AUTOSAR XML (schema 00046)
package /ComponentTypes
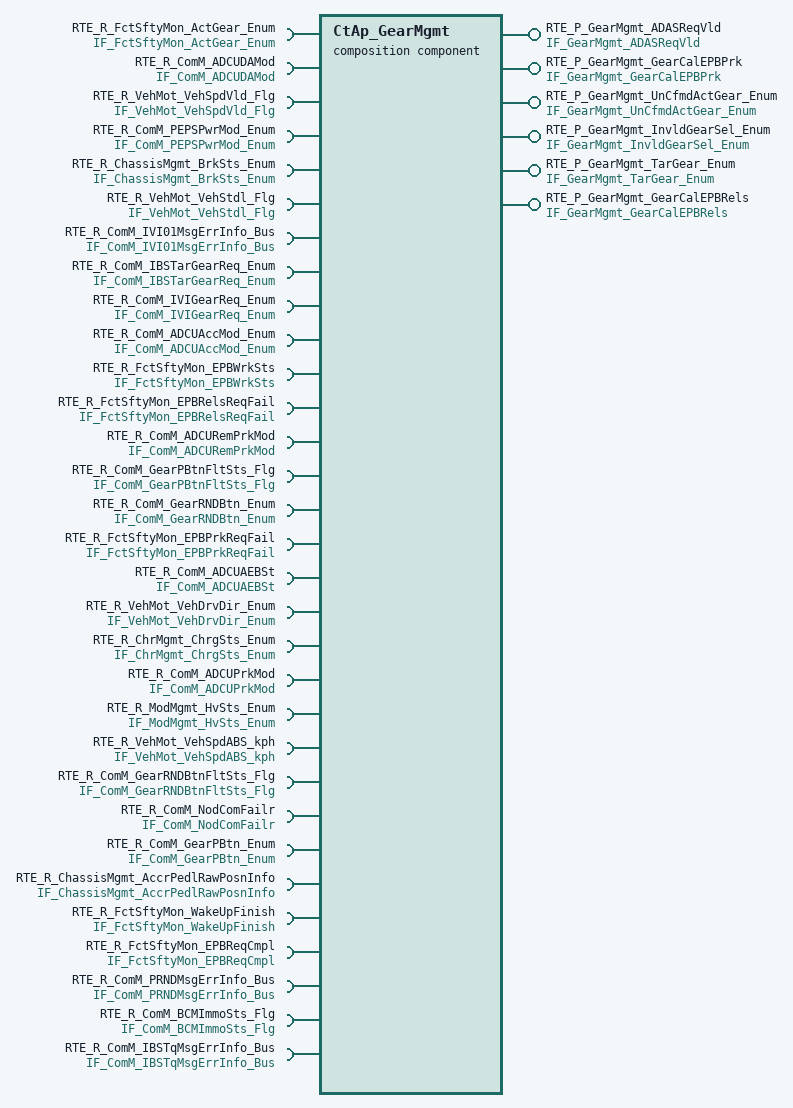
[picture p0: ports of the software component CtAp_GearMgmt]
  composition sw component type CtAp_GearMgmt
    30 x require port:
      RTE_R_FctSftyMon_ActGear_Enum: nonqueued-receiver-com-spec{data-element=tec_FctSftyMon_ActGear_Enum, filter=data-filter-type=ALWAYS, init-value=0}, required-interface=IF_FctSftyMon_ActGear_Enum
      RTE_R_ComM_ADCUDAMod: nonqueued-receiver-com-spec{data-element=tec_ComM_ADCUDAMod, filter=data-filter-type=ALWAYS, init-value=0}, required-interface=IF_ComM_ADCUDAMod
      RTE_R_VehMot_VehSpdVld_Flg: nonqueued-receiver-com-spec{data-element=tec_VehMot_VehSpdVld_Flg, filter=data-filter-type=ALWAYS, init-value=0}, required-interface=IF_VehMot_VehSpdVld_Flg
      RTE_R_ComM_PEPSPwrMod_Enum: nonqueued-receiver-com-spec{data-element=tec_ComM_PEPSPwrMod_Enum, filter=data-filter-type=ALWAYS, init-value=0}, required-interface=IF_ComM_PEPSPwrMod_Enum
      RTE_R_ChassisMgmt_BrkSts_Enum: nonqueued-receiver-com-spec{data-element=tec_ChassisMgmt_BrkSts_Enum, filter=data-filter-type=ALWAYS, init-value=0}, required-interface=IF_ChassisMgmt_BrkSts_Enum
      RTE_R_VehMot_VehStdl_Flg: nonqueued-receiver-com-spec{data-element=tec_VehMot_VehStdl_Flg, filter=data-filter-type=ALWAYS, init-value=0}, required-interface=IF_VehMot_VehStdl_Flg
      RTE_R_ComM_IVI01MsgErrInfo_Bus: required-interface=IF_ComM_IVI01MsgErrInfo_Bus
        required-com-specs:
          data-element=tec_ComM_IVI01CRCInfo_Bus, filter=data-filter-type=ALWAYS, init-value=fields=[ComM_MonStatIVI01CRCErrorInfo:0, ComM_MonResIVI01CRCErrorInfo:0, ComM_ErrStatIVI01CRCErrorInfo:0, ComM_ErrResIVI01CRCErrorInfo:0]
          data-element=tec_ComM_IVI01E2ETimeoutInfo_Bus, filter=data-filter-type=ALWAYS
      RTE_R_ComM_IBSTarGearReq_Enum: nonqueued-receiver-com-spec{data-element=tec_ComM_IBSTarGearReq_Enum, filter=data-filter-type=ALWAYS, init-value=0}, required-interface=IF_ComM_IBSTarGearReq_Enum
      RTE_R_ComM_IVIGearReq_Enum: nonqueued-receiver-com-spec{data-element=tec_ComM_IVIGearReq_Enum, filter=data-filter-type=ALWAYS, init-value=0}, required-interface=IF_ComM_IVIGearReq_Enum
      RTE_R_ComM_ADCUAccMod_Enum: nonqueued-receiver-com-spec{data-element=tec_ComM_ADCUAccMod_Enum, filter=data-filter-type=ALWAYS, init-value=0}, required-interface=IF_ComM_ADCUAccMod_Enum
      RTE_R_FctSftyMon_EPBWrkSts: nonqueued-receiver-com-spec{data-element=tec_FctSftyMon_EPBWrkSts, filter=data-filter-type=ALWAYS, init-value=0}, required-interface=IF_FctSftyMon_EPBWrkSts
      RTE_R_FctSftyMon_EPBRelsReqFail: nonqueued-receiver-com-spec{data-element=tec_FctSftyMon_EPBRelsReqFail, filter=data-filter-type=ALWAYS, init-value=0}, required-interface=IF_FctSftyMon_EPBRelsReqFail
      RTE_R_ComM_ADCURemPrkMod: nonqueued-receiver-com-spec{data-element=tec_ComM_ADCURemPrkMod, filter=data-filter-type=ALWAYS, init-value=0}, required-interface=IF_ComM_ADCURemPrkMod
      RTE_R_ComM_GearPBtnFltSts_Flg: nonqueued-receiver-com-spec{data-element=tec_ComM_GearPBtnFltSts_Flg, filter=data-filter-type=ALWAYS, init-value=0}, required-interface=IF_ComM_GearPBtnFltSts_Flg
      RTE_R_ComM_GearRNDBtn_Enum: nonqueued-receiver-com-spec{data-element=tec_ComM_GearRNDBtn_Enum, filter=data-filter-type=ALWAYS, init-value=0}, required-interface=IF_ComM_GearRNDBtn_Enum
      RTE_R_FctSftyMon_EPBPrkReqFail: nonqueued-receiver-com-spec{data-element=tec_FctSftyMon_EPBPrkReqFail, filter=data-filter-type=ALWAYS, init-value=0}, required-interface=IF_FctSftyMon_EPBPrkReqFail
      RTE_R_ComM_ADCUAEBSt: nonqueued-receiver-com-spec{data-element=tec_ComM_ADCUAEBSt, filter=data-filter-type=ALWAYS, init-value=0}, required-interface=IF_ComM_ADCUAEBSt
      RTE_R_VehMot_VehDrvDir_Enum: nonqueued-receiver-com-spec{data-element=tec_VehMot_VehDrvDir_Enum, filter=data-filter-type=ALWAYS, init-value=0}, required-interface=IF_VehMot_VehDrvDir_Enum
      RTE_R_ChrMgmt_ChrgSts_Enum: nonqueued-receiver-com-spec{data-element=tec_ChrMgmt_ChrgSts_Enum, filter=data-filter-type=ALWAYS, init-value=0}, required-interface=IF_ChrMgmt_ChrgSts_Enum
      RTE_R_ComM_ADCUPrkMod: nonqueued-receiver-com-spec{data-element=tec_ComM_ADCUPrkMod, filter=data-filter-type=ALWAYS, init-value=0}, required-interface=IF_ComM_ADCUPrkMod
      RTE_R_ModMgmt_HvSts_Enum: nonqueued-receiver-com-spec{data-element=tec_ModMgmt_HvSts_Enum, filter=data-filter-type=ALWAYS, init-value=0}, required-interface=IF_ModMgmt_HvSts_Enum
      RTE_R_VehMot_VehSpdABS_kph: nonqueued-receiver-com-spec{data-element=tec_VehMot_VehSpdABS_kph, filter=data-filter-type=ALWAYS, init-value=0}, required-interface=IF_VehMot_VehSpdABS_kph
      RTE_R_ComM_GearRNDBtnFltSts_Flg: nonqueued-receiver-com-spec{data-element=tec_ComM_GearRNDBtnFltSts_Flg, filter=data-filter-type=ALWAYS, init-value=0}, required-interface=IF_ComM_GearRNDBtnFltSts_Flg
      RTE_R_ComM_NodComFailr: required-interface=IF_ComM_NodComFailr
        required-com-specs:
          data-element=tec_ComM_DCMRRNodComFailr_Flg, filter=data-filter-type=ALWAYS, init-value=0
          data-element=tec_ComM_DCMRLNodComFailr_Flg, filter=data-filter-type=ALWAYS, init-value=0
          data-element=tec_ComM_DCMFRNodComFailr_Flg, filter=data-filter-type=ALWAYS, init-value=0
          data-element=tec_ComM_DCMFLNodComFailr_Flg, filter=data-filter-type=ALWAYS, init-value=0
          data-element=tec_ComM_APTCNodComFailr_Flg, filter=data-filter-type=ALWAYS, init-value=0
          data-element=tec_ComM_ADCUNodComFailr_Flg, filter=data-filter-type=ALWAYS, init-value=0
          data-element=tec_ComM_ACUNodComFailr_Flg, filter=data-filter-type=ALWAYS, init-value=0
          data-element=tec_ComM_SGWNodComFailr_Flg, filter=data-filter-type=ALWAYS, init-value=0
          data-element=tec_ComM_CGWNodComFailr_Flg, filter=data-filter-type=ALWAYS, init-value=0
          data-element=tec_ComM_TCUNodComFailr_Flg, filter=data-filter-type=ALWAYS, init-value=0
          data-element=tec_ComM_BCMNodComFailr_Flg, filter=data-filter-type=ALWAYS, init-value=0
          data-element=tec_ComM_PRNDNodComFailr_Flg, filter=data-filter-type=ALWAYS, init-value=0
          data-element=tec_ComM_IVINodComFailr_Flg, filter=data-filter-type=ALWAYS, init-value=0
          data-element=tec_ComM_DCDCNodComFailr_Flg, filter=data-filter-type=ALWAYS, init-value=0
          data-element=tec_ComM_OBCNodComFailr_Flg, filter=data-filter-type=ALWAYS, init-value=0
          data-element=tec_ComM_CHIBSNodComFailr_Flg, filter=data-filter-type=ALWAYS, init-value=0
          data-element=tec_ComM_MCUNodComFailr_Flg, filter=data-filter-type=ALWAYS, init-value=0
          data-element=tec_ComM_EVCOMNodComFailr_Flg, filter=data-filter-type=ALWAYS, init-value=0
          data-element=tec_ComM_EPTIBSNodComFailr_Flg, filter=data-filter-type=ALWAYS, init-value=0
          data-element=tec_ComM_DCMNodComFailr_Flg, filter=data-filter-type=ALWAYS, init-value=0
          data-element=tec_ComM_BMSNodComFailr_Flg, filter=data-filter-type=ALWAYS, init-value=0
          data-element=tec_ComM_SGWCHNodComFailr_Flg, filter=data-filter-type=ALWAYS, init-value=0
      RTE_R_ComM_GearPBtn_Enum: nonqueued-receiver-com-spec{data-element=tec_ComM_GearPBtn_Enum, filter=data-filter-type=ALWAYS, init-value=0}, required-interface=IF_ComM_GearPBtn_Enum
      RTE_R_ChassisMgmt_AccrPedlRawPosnInfo: nonqueued-receiver-com-spec{data-element=tec_ChassisMgmt_AccrPedlRawPosnInfo, filter=data-filter-type=ALWAYS, init-value=0}, required-interface=IF_ChassisMgmt_AccrPedlRawPosnInfo
      RTE_R_FctSftyMon_WakeUpFinish: nonqueued-receiver-com-spec{data-element=tec_FctSftyMon_WakeUpFinish, filter=data-filter-type=ALWAYS, init-value=0}, required-interface=IF_FctSftyMon_WakeUpFinish
      RTE_R_FctSftyMon_EPBReqCmpl: nonqueued-receiver-com-spec{data-element=tec_FctSftyMon_EPBReqCmpl, filter=data-filter-type=ALWAYS, init-value=0}, required-interface=IF_FctSftyMon_EPBReqCmpl
      RTE_R_ComM_PRNDMsgErrInfo_Bus: required-interface=IF_ComM_PRNDMsgErrInfo_Bus
        required-com-specs:
          data-element=tec_ComM_PRNDTimeoutInfo_Bus, filter=data-filter-type=ALWAYS, init-value=fields=[ComM_MonStatPRNDTimeoutInfo:0, ComM_MonResPRNDTimeoutInfo:0, ComM_ErrStatPRNDTimeoutInfo:0, ComM_ErrResPRNDTimeoutInfo:0]
          data-element=tec_ComM_PRNDCRCDTCInfo_Bus, filter=data-filter-type=ALWAYS, init-value=fields=[ComM_MonStatPRNDCRCDTCErrorInfo:0, ComM_MonResPRNDCRCDTCErrorInfo:0, ComM_ErrStatPRNDCRCDTCErrorInfo:0, ComM_ErrResPRNDCRCDTCErrorInfo:0]
          data-element=tec_ComM_PRNDCRCInfo_Bus, filter=data-filter-type=ALWAYS, init-value=fields=[ComM_MonStatPRNDCRCErrorInfo:0, ComM_MonResPRNDCRCErrorInfo:0, ComM_ErrStatPRNDCRCErrorInfo:0, ComM_ErrResPRNDCRCErrorInfo:0]
          data-element=tec_ComM_PRNDTimeoutDTCInfo_Bus, filter=data-filter-type=ALWAYS, init-value=fields=[ComM_MonStatPRNDTimeoutDTCErrorInfo:0, ComM_MonResPRNDTimeoutDTCErrorInfo:0, ComM_ErrStatPRNDTimeoutDTCErrorInfo:0, ComM_ErrResPRNDTimeoutDTCErrorInfo:0]
          data-element=tec_ComM_PRNDE2ETimeoutInfo_Bus, filter=data-filter-type=ALWAYS, init-value=fields=[ComM_MonStatPRNDE2ETimeoutInfo:0, ComM_MonResPRNDE2ETimeoutInfo:0, ComM_ErrStatPRNDE2ETimeoutInfo:0, ComM_ErrResPRNDE2ETimeoutInfo:0]
      RTE_R_ComM_BCMImmoSts_Flg: nonqueued-receiver-com-spec{data-element=tec_ComM_BCMImmoSts_Flg, filter=data-filter-type=ALWAYS, init-value=0}, required-interface=IF_ComM_BCMImmoSts_Flg
    6 x provide port:
      RTE_P_GearMgmt_ADASReqVld: nonqueued-sender-com-spec{data-element=tec_GearMgmt_ADASReqVld, init-value=0}, provided-interface=IF_GearMgmt_ADASReqVld
      RTE_P_GearMgmt_GearCalEPBPrk: nonqueued-sender-com-spec{data-element=tec_GearMgmt_GearCalEPBPrk, init-value=0}, provided-interface=IF_GearMgmt_GearCalEPBPrk
      RTE_P_GearMgmt_UnCfmdActGear_Enum: nonqueued-sender-com-spec{data-element=tec_GearMgmt_UnCfmdActGear_Enum, init-value=0}, provided-interface=IF_GearMgmt_UnCfmdActGear_Enum
      RTE_P_GearMgmt_InvldGearSel_Enum: nonqueued-sender-com-spec{data-element=tec_GearMgmt_InvldGearSel_Enum, init-value=0}, provided-interface=IF_GearMgmt_InvldGearSel_Enum
      RTE_P_GearMgmt_TarGear_Enum: nonqueued-sender-com-spec{data-element=tec_GearMgmt_TarGear_Enum, init-value=0}, provided-interface=IF_GearMgmt_TarGear_Enum
      RTE_P_GearMgmt_GearCalEPBRels: nonqueued-sender-com-spec{data-element=tec_GearMgmt_GearCalEPBRels, init-value=0}, provided-interface=IF_GearMgmt_GearCalEPBRels
    require port RTE_R_ComM_IBSTqMsgErrInfo_Bus: required-interface=IF_ComM_IBSTqMsgErrInfo_Bus
      required-com-specs:
        data-element=tec_ComM_IBSTqCRCDTCInfo_Bus, filter=data-filter-type=ALWAYS, init-value=fields=[ComM_MonStatIBSTqCRCDTCErrorInfo:0, ComM_MonResIBSTqCRCDTCErrorInfo:0, ComM_ErrStatIBSTqCRCDTCErrorInfo:0, ComM_ErrResIBSTqCRCDTCErrorInfo:0]
        data-element=tec_ComM_IBSTqTimeoutDTCInfo_Bus, filter=data-filter-type=ALWAYS, init-value=fields=[ComM_MonStatIBSTqTimeoutDTCErrorInfo:0, ComM_MonResIBSTqTimeoutDTCErrorInfo:0, ComM_ErrStatIBSTqTimeoutDTCErrorInfo:0, ComM_ErrResIBSTqTimeoutDTCErrorInfo:0]
        data-element=tec_ComM_IBSTqCRCInfo_Bus, filter=data-filter-type=ALWAYS, init-value=fields=[ComM_MonStatIBSTqCRCErrorInfo:0, ComM_MonResIBSTqCRCErrorInfo:0, ComM_ErrStatIBSTqCRCErrorInfo:0, ComM_ErrResIBSTqCRCErrorInfo:0]
        data-element=tec_ComM_IBSTqE2ETimeoutInfo_Bus, filter=data-filter-type=ALWAYS, init-value=fields=[ComM_MonStatIBSTqE2ETimeoutInfo:0, ComM_MonResIBSTqE2ETimeoutInfo:0, ComM_ErrStatIBSTqE2ETimeoutInfo:0, ComM_ErrResIBSTqE2ETimeoutInfo:0]
    component CtAp_GearCal: type=CtAp_GearCal
    delegate CtAp_GearCal.RTE_R_FctSftyMon_ActGear_Enum <-> outer port RTE_R_FctSftyMon_ActGear_Enum
    delegate CtAp_GearCal.RTE_R_ComM_ADCUDAMod <-> outer port RTE_R_ComM_ADCUDAMod
    delegate CtAp_GearCal.RTE_R_VehMot_VehSpdVld_Flg <-> outer port RTE_R_VehMot_VehSpdVld_Flg
    delegate CtAp_GearCal.RTE_R_ComM_PEPSPwrMod_Enum <-> outer port RTE_R_ComM_PEPSPwrMod_Enum
    delegate CtAp_GearCal.RTE_R_ChassisMgmt_BrkSts_Enum <-> outer port RTE_R_ChassisMgmt_BrkSts_Enum
    delegate CtAp_GearCal.RTE_R_VehMot_VehStdl_Flg <-> outer port RTE_R_VehMot_VehStdl_Flg
    delegate CtAp_GearCal.RTE_R_ComM_IVI01MsgErrInfo_Bus <-> outer port RTE_R_ComM_IVI01MsgErrInfo_Bus
    delegate CtAp_GearCal.RTE_R_ComM_IBSTarGearReq_Enum <-> outer port RTE_R_ComM_IBSTarGearReq_Enum
    delegate CtAp_GearCal.RTE_R_ComM_IVIGearReq_Enum <-> outer port RTE_R_ComM_IVIGearReq_Enum
    delegate CtAp_GearCal.RTE_R_ComM_ADCUAccMod_Enum <-> outer port RTE_R_ComM_ADCUAccMod_Enum
    delegate CtAp_GearCal.RTE_R_FctSftyMon_EPBWrkSts <-> outer port RTE_R_FctSftyMon_EPBWrkSts
    delegate CtAp_GearCal.RTE_R_FctSftyMon_EPBRelsReqFail <-> outer port RTE_R_FctSftyMon_EPBRelsReqFail
    delegate CtAp_GearCal.RTE_R_ComM_ADCURemPrkMod <-> outer port RTE_R_ComM_ADCURemPrkMod
    delegate CtAp_GearCal.RTE_R_ComM_GearPBtnFltSts_Flg <-> outer port RTE_R_ComM_GearPBtnFltSts_Flg
    delegate CtAp_GearCal.RTE_R_ComM_GearRNDBtn_Enum <-> outer port RTE_R_ComM_GearRNDBtn_Enum
    delegate CtAp_GearCal.RTE_R_FctSftyMon_EPBPrkReqFail <-> outer port RTE_R_FctSftyMon_EPBPrkReqFail
    delegate CtAp_GearCal.RTE_R_ComM_ADCUAEBSt <-> outer port RTE_R_ComM_ADCUAEBSt
    delegate CtAp_GearCal.RTE_R_VehMot_VehDrvDir_Enum <-> outer port RTE_R_VehMot_VehDrvDir_Enum
    delegate CtAp_GearCal.RTE_R_ChrMgmt_ChrgSts_Enum <-> outer port RTE_R_ChrMgmt_ChrgSts_Enum
    delegate CtAp_GearCal.RTE_R_ComM_ADCUPrkMod <-> outer port RTE_R_ComM_ADCUPrkMod
    delegate CtAp_GearCal.RTE_R_ModMgmt_HvSts_Enum <-> outer port RTE_R_ModMgmt_HvSts_Enum
    delegate CtAp_GearCal.RTE_R_VehMot_VehSpdABS_kph <-> outer port RTE_R_VehMot_VehSpdABS_kph
    delegate CtAp_GearCal.RTE_R_ComM_GearRNDBtnFltSts_Flg <-> outer port RTE_R_ComM_GearRNDBtnFltSts_Flg
    delegate CtAp_GearCal.RTE_R_ComM_NodComFailr <-> outer port RTE_R_ComM_NodComFailr
    delegate CtAp_GearCal.RTE_R_ComM_GearPBtn_Enum <-> outer port RTE_R_ComM_GearPBtn_Enum
    delegate CtAp_GearCal.RTE_R_ChassisMgmt_AccrPedlRawPosnInfo <-> outer port RTE_R_ChassisMgmt_AccrPedlRawPosnInfo
    delegate CtAp_GearCal.RTE_R_FctSftyMon_WakeUpFinish <-> outer port RTE_R_FctSftyMon_WakeUpFinish
    delegate CtAp_GearCal.RTE_R_FctSftyMon_EPBReqCmpl <-> outer port RTE_R_FctSftyMon_EPBReqCmpl
    delegate CtAp_GearCal.RTE_R_ComM_PRNDMsgErrInfo_Bus <-> outer port RTE_R_ComM_PRNDMsgErrInfo_Bus
    delegate CtAp_GearCal.RTE_R_ComM_BCMImmoSts_Flg <-> outer port RTE_R_ComM_BCMImmoSts_Flg
    delegate CtAp_GearCal.RTE_P_GearMgmt_ADASReqVld <-> outer port RTE_P_GearMgmt_ADASReqVld
    delegate CtAp_GearCal.RTE_P_GearMgmt_GearCalEPBPrk <-> outer port RTE_P_GearMgmt_GearCalEPBPrk
    delegate CtAp_GearCal.RTE_P_GearMgmt_UnCfmdActGear_Enum <-> outer port RTE_P_GearMgmt_UnCfmdActGear_Enum
    delegate CtAp_GearCal.RTE_P_GearMgmt_InvldGearSel_Enum <-> outer port RTE_P_GearMgmt_InvldGearSel_Enum
    delegate CtAp_GearCal.RTE_P_GearMgmt_TarGear_Enum <-> outer port RTE_P_GearMgmt_TarGear_Enum
    delegate CtAp_GearCal.RTE_P_GearMgmt_GearCalEPBRels <-> outer port RTE_P_GearMgmt_GearCalEPBRels
    delegate CtAp_GearCal.RTE_R_ComM_IBSTqMsgErrInfo_Bus <-> outer port RTE_R_ComM_IBSTqMsgErrInfo_Bus
